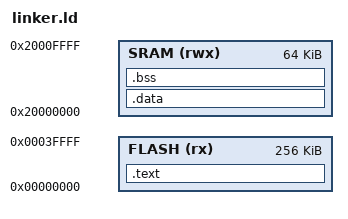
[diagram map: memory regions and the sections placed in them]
/*
 * NanOS ARM Cortex-M3 Linker Script
 * Target: QEMU lm3s6965evb (Stellaris)
 *
 * Memory Map:
 *   Flash: 0x00000000 - 256KB
 *   SRAM:  0x20000000 - 64KB
 */

MEMORY
{
    FLASH (rx)  : ORIGIN = 0x00000000, LENGTH = 256K
    SRAM  (rwx) : ORIGIN = 0x20000000, LENGTH = 64K
}

ENTRY(Reset_Handler)

SECTIONS
{
    /* Vector table and code */
    .text :
    {
        KEEP(*(.vectors))
        *(.text*)
        *(.rodata*)
        . = ALIGN(4);
        _etext = .;
    } > FLASH

    /* Initialized data */
    .data : AT(_etext)
    {
        _sdata = .;
        *(.data*)
        . = ALIGN(4);
        _edata = .;
    } > SRAM

    /* Uninitialized data */
    .bss :
    {
        _sbss = .;
        *(.bss*)
        *(COMMON)
        . = ALIGN(4);
        _ebss = .;
    } > SRAM

    /* Stack at end of SRAM */
    _stack_top = ORIGIN(SRAM) + LENGTH(SRAM);
}
